# R7FA6T3BB register map
Vendor: Renesas Electronics Corporation; Series: RA6; File version: 1.10.01
CPU: CM33 r0p4, little endian, MPU, FPU, VTOR, 4 interrupt priority bits, 96 interrupts
Registers are 32-bit, read-write, reset 0x0 unless marked. A register's access mark holds for its fields unless they carry their own. Offsets are from the block's base; [hi:lo] are bit positions; {n}, {i} and the like mark numbered series; 'fields as' and 'values as' point back to an identical list.

## I3C — I3C Bus Interface
Base 0x4011F000
0x00 PRTS reset 0x1 — Protocol Selection Register
  [0] PRTMD — Protocol Mode
    0=I3C protocol mode; 1=I2C protocol mode
0x10 CECTL — Clock Enable Control Resisters
  [0] CLKE — Clock Enable
    0=Clock disable; 1=Clock enable
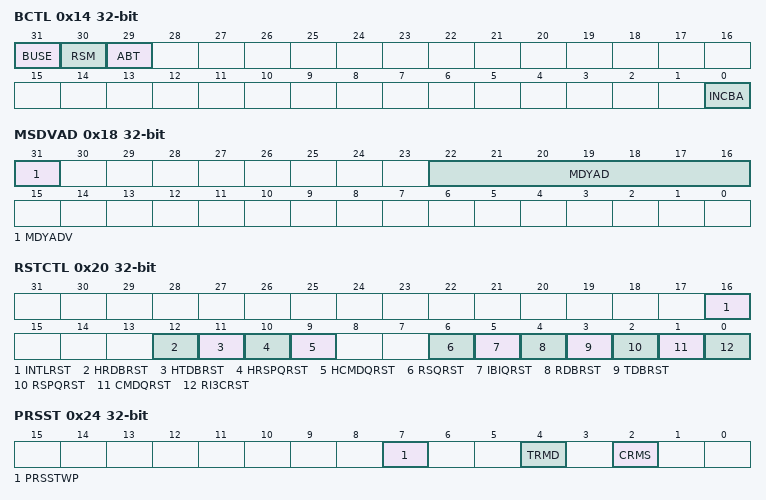
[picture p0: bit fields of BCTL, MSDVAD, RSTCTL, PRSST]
0x14 BCTL — Bus Control Register
  [31] BUSE — Bus Enable
    0=I3C bus operation is disabled; 1=I3C bus operation is enabled
  [30] RSM — Resume
    0=I3C is running; 1=I3C is suspended
  [29] ABT — Abort
    0=I3C is running; 1=I3C has aborted a transfer
  [0] INCBA — Include I3C Broadcast Address
    0=Do not include I3C broadcast address for private transfers; 1=Include I3C broadcast address for private transfers
0x18 MSDVAD — Master Device Address Register
  [31] MDYADV — Master Dynamic Address Valid
    0=The master dynamic address field is not valid; 1=The master dynamic address field is valid
  [22:16] MDYAD — Master Dynamic Address
0x20 RSTCTL — Reset Control Register
  [16] INTLRST — Internal Software Reset
    0=Releases of some registers and internal state; 1=Resets of some registers and internal state
  [12] HRDBRST — High Priority Receive Data Buffer Software Reset
    0=The High Priority Receive Queues in I3C is not flushed; 1=The High Priority Receive Queues in I3C is flushed
  [11] HTDBRST — High Priority Transmit Data Buffer Software Reset
    0=The High Priority Transmit Queues in I3C is not flushed; 1=The High Priority Transmit Queues in I3C is flushed
  [10] HRSPQRST — High Priority Response Queue Software Reset
    0=The High Priority Response Queues in I3C is not flushed; 1=The High Priority Response Queues in I3C is flushed
  [9] HCMDQRST — High Priority Command Queue Software Reset
    0=The High Priority Command Queues in I3C is not flushed; 1=The High Priority Command Queues in I3C is flushed
  [6] RSQRST — Receive Status Queue Software Reset
    0=The Receive Status Queue in I3C is not flushed; 1=The Receive Status Queue in I3C is flushed
  [5] IBIQRST — IBI Queue Software Reset
    0=The IBI Queues in I3C is not flushed; 1=The IBI Queues in I3C is flushed
  [4] RDBRST — Receive Data Buffer Software Reset
    0=The Receive Queues in I3C is not flushed; 1=The Receive Queues in I3C is flushed
  [3] TDBRST — Transmit Data Buffer Software Reset
    0=The Transmit Queues in I3C is not flushed; 1=The Transmit Queues in I3C is flushed
  [2] RSPQRST — Response Queue Software Reset
    0=The Response Queues in I3C is not flushed; 1=The Response Queues in I3C is flushed
  [1] CMDQRST — Command Queue Software Reset
    0=The Command Queues in I3C is not flushed; 1=The Command Queues in I3C is flushed
  [0] RI3CRST — I3C Software Reset
    0=Release I3C reset; 1=Initiate I3C reset
0x24 PRSST — Present State Register
  [7] PRSSTWP wo — Present State Write Protect
    0=CRMS bit is protected; 1=CRMS bit can be written when writing simultaneously with the value of the target bit
  [4] TRMD ro — Transmit/Receive Mode
    0=Receive mode; 1=Transmit mode
  [2] CRMS — Current Master
    0=The Master is not the Current Master, and must request and acquire bus ownership before initiating any transfer; 1=The Master is the Current Master, and as a result can initiate transfers
0x30 INST — Internal Status Register
  [10] INEF — Internal Error Flag
    0=I3C Internal Error has not detected; 1=I3C Internal Error has detected
0x34 INSTE — Internal Status Enable Register
  [10] INEE — Internal Error Enable
    0=Disable INST.INEF; 1=Enable INST.INEF
0x38 INIE — Internal Interrupt Enable Register
  [10] INEIE — Internal Error Interrupt Enable
    0=Disables Non-recoverable Internal Error Interrupt Signal; 1=Enables Non-recoverable Internal Error Interrupt Signal
0x3C INSTFC wo — Internal Status Force Register
  [10] INEFC — Internal Error Force
    0=Not force a specific interrupt; 1=Force a specific interrupt
0x44 DVCT ro — Device Characteristic Table Register
  [23:19] IDX — DCT Table Index
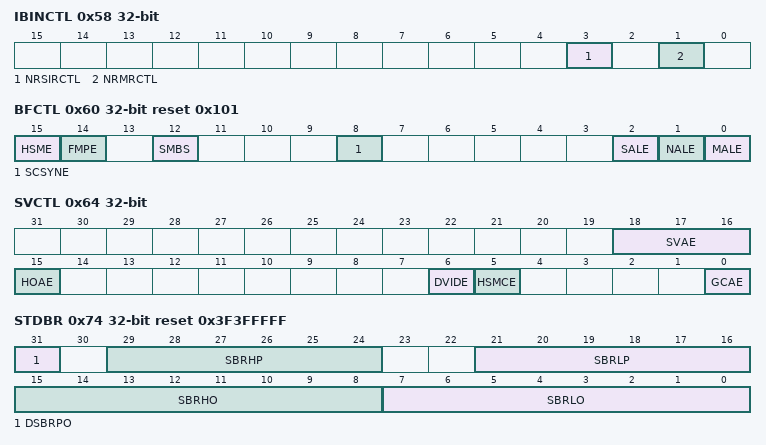
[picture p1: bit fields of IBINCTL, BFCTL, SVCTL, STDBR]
0x58 IBINCTL — IBI Notify Control Register
  [3] NRSIRCTL — Notify Rejected Slave Interrupt Request Control
    0=Do not pass rejected IBI Status to the IBI Queue/Rings, if the incoming SIR is NACKed and is auto-disabled based on DVSIRRJ field in relevant DAT entry; 1=Pass rejected IBI Status to the IBI Queue/Rings, if the incoming SIR is NACKed and is auto-disabled based on DVSIRRJ field in relevant DAT entry
  [1] NRMRCTL — Notify Rejected Master Request Control
    0=Do not pass rejected IBI Status to IBI Queue/Ring, if the incoming Master Request is NACKed and is auto-disabled based on DVMRRJ field in relevant DAT entry; 1=Pass rejected IBI Status to the IBI Queue, if the incoming Master Request is NACKed and is autodisabled based on DVMRRJ field in relevant DAT entry
0x60 BFCTL reset 0x101 — Bus Function Control Register
  [15] HSME — High Speed Mode Enable
    0=Disable High Speed Mode; 1=Enable High Speed Mode
  [14] FMPE — Fast-mode Plus Enable
    0=No Fm+ slope control circuit uses for the I3C_SCL pin and I3C_SDA pin. (n = 0); 1=An Fm+ slope control circuit uses for the I3C_SCL pin and I3C_SDA pin. (n = 0)
  [12] SMBS — SMBus/I2C Bus Selection
    0=The I2C bus select; 1=The SMBus select
  [8] SCSYNE — SCL Synchronous Circuit Enable
    0=No SCL synchronous circuit uses; 1=An SCL synchronous circuit uses
  [2] SALE — Slave Arbitration-Lost Detection Enable
    0=Slave arbitration-lost detection disables; 1=Slave arbitration-lost detection enables
  [1] NALE — NACK Transmission Arbitration-Lost Detection Enable
    0=NACK transmission arbitration-lost detection disables; 1=NACK transmission arbitration-lost detection enables
  [0] MALE — Master Arbitration-Lost Detection Enable
    0=Master arbitration-lost detection disables. Disables the arbitration-lost detection function and does not clear the CRMS and TRMD bits in PRSST automatically when arbitration is lost.; 1=Master arbitration-lost detection enables. Enables the arbitration-lost detection function and clears the CRMS and TRMD bits in PRSST automatically when arbitration is lost.
0x64 SVCTL — Slave Control Register
  [18:16] SVAE — Slave Address Enable n ( n = 0 to 2 )
    0=Slave n disables; 1=Slave n enables
  [15] HOAE — Host Address Enable
    0=Host address detection disables; 1=Host address detection enables
  [6] DVIDE — Device-ID Address Enable
    0=Device-ID address detection disables; 1=Device-ID address detection enables
  [5] HSMCE — Hs-mode Master Code Enable
    0=Hs-mode Master Code Detection disables; 1=Hs-mode Master Code Detection enables
  [0] GCAE — General Call Address Enable
    0=General call address detection disables; 1=General call address detection enables
0x70 REFCKCTL — Reference Clock Control Register
  [2:0] IREFCKS — Internal Reference Clock Selection
    0=TCLK/1 clock; 1=TCLK/2 clock; 2=TCLK/4 clock; 3=TCLK/8 clock; 4=TCLK/16 clock; 5=TCLK/32 clock; 6=TCLK/64 clock; 7=TCLK/128 clock
0x74 STDBR reset 0x3F3FFFFF — Standard Bit Rate Register
  [31] DSBRPO — Double the Standard Bit Rate Period for Open-Drain
    0=The time period set for SBRHO[7:0] and SBRLO[7:0] is not doubled; 1=The time period set for SBRHO[7:0] and SBRLO[7:0] is doubled
  [29:24] SBRHP — Standard Bit Rate High-level Period Push-Pull
  [21:16] SBRLP — Standard Bit Rate Low-level Period Push-Pull
  [15:8] SBRHO — Standard Bit Rate High-level Period Open-Drain
  [7:0] SBRLO — Standard Bit Rate Low-level Period Open-Drain
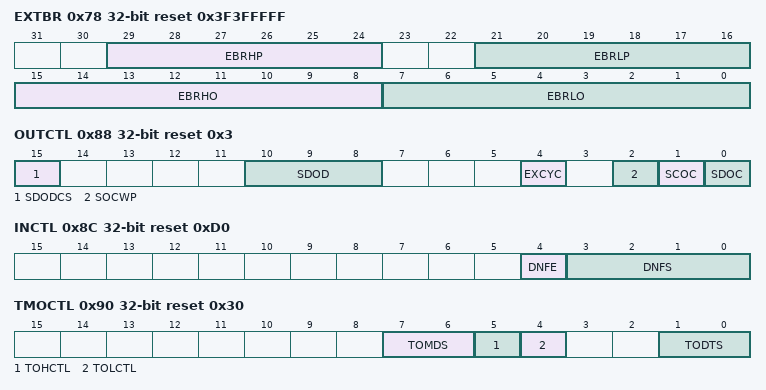
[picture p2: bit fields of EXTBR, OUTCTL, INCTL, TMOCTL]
0x78 EXTBR reset 0x3F3FFFFF — Extended Bit Rate Register
  [29:24] EBRHP — Extended Bit Rate High-level Period Push-Pull
  [21:16] EBRLP — Extended Bit Rate Low-level Period Push-Pull
  [15:8] EBRHO — Extended Bit Rate High-level Period Open-Drain
  [7:0] EBRLO — Extended Bit Rate Low-level Period Open-Drain
0x7C BFRECDT — Bus Free Condition Detection Time Register
  [8:0] FRECYC — Bus Free Condition Detection Cycle
0x80 BAVLCDT — Bus Available Condition Detection Time Register
  [8:0] AVLCYC — Bus Available Condition Detection Cycle
0x84 BIDLCDT — Bus Idle Condition Detection Time Register
  [17:0] IDLCYC — Bus Idle Condition Detection Cycle
0x88 OUTCTL reset 0x3 — Output Control Register
  [15] SDODCS — SDA Output Delay Clock Source Selection
    0=The internal reference clock (I3Cφ) is selected as the clock source of the SDA output delay counter; 1=The internal reference clock divided by 2 (I3Cφ/2) is selected as the clock source of the SDA output delay counter
  [10:8] SDOD — SDA Output Delay
    0=No output delay; 1=1 I3Cφ cycle (When OUTCTL.SDODCS = 0 (I3Cφ)) 1 or 2 I3Cφ cycles (When OUTCTL.SDODCS = 1 (I3Cφ/2)); 2=2 I3Cφ cycles (When OUTCTL.SDODCS = 0 (I3Cφ)) 3 or 4 I3Cφ cycles (When OUTCTL.SDODCS = 1 (I3Cφ/2)); 3=3 I3Cφ cycles (When OUTCTL.SDODCS = 0 (I3Cφ)) 5 or 6 I3Cφ cycles (When OUTCTL.SDODCS = 1 (I3Cφ/2)); 4=4 I3Cφ cycles (When OUTCTL.SDODCS = 0 (I3Cφ)) 7 or 8 I3Cφ cycles (When OUTCTL.SDODCS = 1 (I3Cφ/2)); 5=5 I3Cφ cycles (When OUTCTL.SDODCS = 0 (I3Cφ)) 9 or 10 I3Cφ cycles (When OUTCTL.SDODCS = 1 (I3Cφ/2)); 6=6 I3Cφ cycles (When OUTCTL.SDODCS = 0 (I3Cφ)) 11 or 12 I3Cφ cycles (When OUTCTL.SDODCS = 1 (I3Cφ/2)); 7=7 I3Cφ cycles (When OUTCTL.SDODCS = 0 (I3Cφ)) 13 or 14 I3Cφ cycles (When OUTCTL.SDODCS = 1 (I3Cφ/2))
  [4] EXCYC — Extra SCL Clock Cycle Output
    0=Does not output an extra SCL clock cycle (default); 1=Outputs an extra SCL clock cycle
  [2] SOCWP wo — SCL/SDA Output Control Write Protect
    0=Bits SCOC and SDOC are protected; 1=Bits SCOC and SDOC can be written (When writing simultaneously with the value of the target bit). This bit is read as 0.
  [1] SCOC — SCL Output Control
    0=I3C drives the I3C_SCL pin low; 1=I3C releases the I3C_SCL pin
  [0] SDOC — SDA Output Control
    0=I3C drives the I3C_SDA pin low; 1=I3C releases the I3C_SDA pin
0x8C INCTL reset 0xD0 — Input Control Register
  [4] DNFE — Digital Noise Filter Circuit Enable
    0=No digital noise filter circuit is used; 1=A digital noise filter circuit is used
  [3:0] DNFS — Digital Noise Filter Stage Selection
0x90 TMOCTL reset 0x30 — Timeout Control Register
  [7:6] TOMDS — Timeout Operation Mode Selection
    0=Timeout is detected during the following conditions: The bus is busy (BCST.BFREF = 0) in master mode.I3C’s own slave address is detected and the bus is busy in slave mode.The bus is free (BCST.BFREF = 1) while generation of a START condition is requested (CNDCTL.STCND = 1); 1=Timeout is detected while the bus is busy; 2=Timeout is detected while the bus is free; 3=Setting prohibited
  [5] TOHCTL — Timeout H Count Control
    0=Count is disabled while the I3C_SCL line is at a high level; 1=Count is enabled while the I3C_SCL line is at a high level
  [4] TOLCTL — Timeout L Count Control
    0=Count is disabled while the I3C_SCL line is at a low level; 1=Count is enabled while the I3C_SCL line is at a low level
  [1:0] TODTS — Timeout Detection Time Selection
    0=16bit-timeout; 1=14bit-timeout; 2=8bit-timeout; 3=6bit-timeout
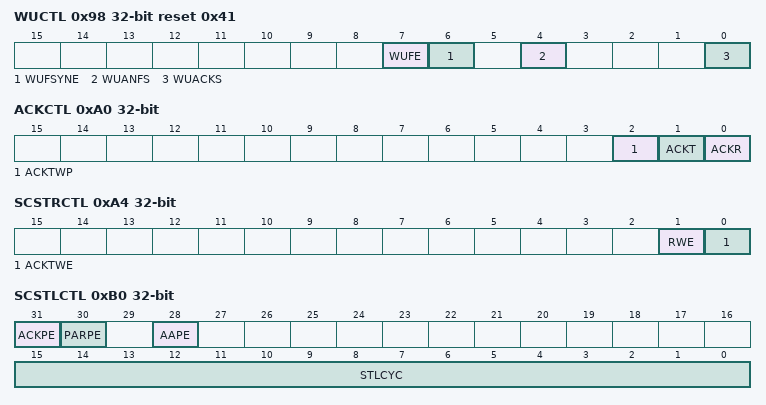
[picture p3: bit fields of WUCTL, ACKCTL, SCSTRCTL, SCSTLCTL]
0x98 WUCTL reset 0x41 — Wake Up Unit Control Register
  [7] WUFE — Wake-Up function Enable
    0=Wake-up function disables; 1=Wake-up function enables
  [6] WUFSYNE — Wake-Up function PCLK Synchronous Enable
    0=I3C asynchronous circuit enable; 1=I3C synchronous circuit enable
  [4] WUANFS — Wake-Up Analog Noise Filter Selection
    0=Do not add the Wake Up analog filter; 1=Add the Wake Up analog filter
  [0] WUACKS — Wake-Up Acknowledge Selection
0xA0 ACKCTL — Acknowledge Control Register
  [2] ACKTWP wo — ACKT Write Protect
    0=The ACKT bit are protected; 1=The ACKT bit can be written (when writing simultaneously with the value of the target bit). This bit is read as 0.
  [1] ACKT — Acknowledge Transmission
    0=A 0 is sent as the acknowledge bit (ACK transmission); 1=A 1 is sent as the acknowledge bit (NACK transmission)
  [0] ACKR ro — Acknowledge Reception
    0=A 0 is received as the acknowledge bit (ACK reception); 1=A 1 is received as the acknowledge bit (NACK reception)
0xA4 SCSTRCTL — SCL Stretch Control Register
  [1] RWE — Receive Wait Enable
    0=No WAIT (The period between ninth clock cycle and first clock cycle is not held low.); 1=WAIT (The period between ninth clock cycle and first clock cycle is held low.) Low-hold is released by reading NTDTBP0
  [0] ACKTWE — Acknowledge Transmission Wait Enable
    0=NTST.RDBFF0 is set at the rising edge of the ninth SCL clock cycle. (The I3C_SCL line is not held low at the falling edge of the eighth clock cycle.); 1=NTST.RDBFF0 is set at the rising edge of the eighth SCL clock cycle. (The I3C_SCL line is held low at the falling edge of the eighth clock cycle.) Low-hold is released by writing a value to the ACKCTL.ACKT bit.
0xB0 SCSTLCTL — SCL Stalling Control Register
  [31] ACKPE — ACK phase Enable
    0=Does not stall the SCL clock during the ACK/NACK phase; 1=Stall the SCL clock during the ACK/NACK phase
  [30] PARPE — Parity Phase Enable
    0=Does not stall the SCL clock during the parity bit period; 1=Stall the SCL clock during the parity bit period
  [28] AAPE — Assigned Address Phase Enable
    0=Does not stall the SCL clock during the address assignment phase; 1=Stall the SCL clock during address assignment phase
  [15:0] STLCYC — Stalling Cycle
0xC0 SVTDLG0 — Slave Transfer Data Length Register 0
  [31:16] STDLG — Slave Transfer Data Length
0x120 STCTL — Synchronous Timing Control Register
  [0] STOE — Synchronous Timing output Enable
    0=Disable; 1=Enable
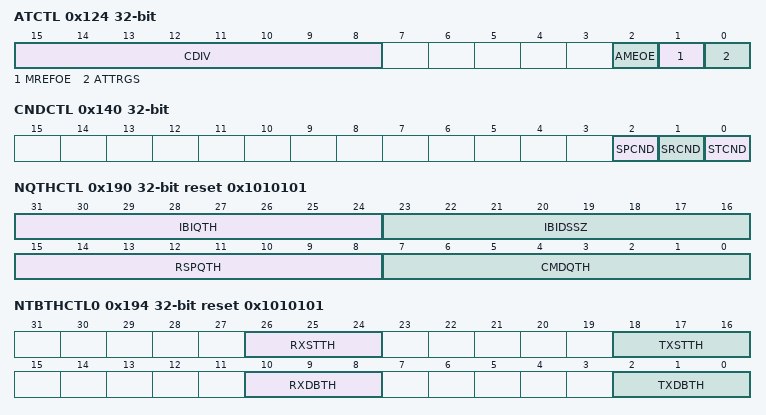
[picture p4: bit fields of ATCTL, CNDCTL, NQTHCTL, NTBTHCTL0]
0x124 ATCTL — Asynchronous Timing Control Register
  [15:8] CDIV — TCLK Counter Divide Setting
  [2] AMEOE — Additional Master-initiated bus Event Output Enable
    0=Disable; 1=Enable
  [1] MREFOE — MREF Output Enable (Capture Event / Counter Overflow)
    0=Disable; 1=Enable
  [0] ATTRGS — Asynchronous Timing Trigger Select
    0=Software trigger; 1=Hardware trigger
0x128 ATTRG — Asynchronous Timing Trigger Register
  [0] ATSTRG wo — Asynchronous Timing Software Trigger
    0=Do nothing; 1=Software trigger (one-shot pulse) output This bit is always read as 0
0x12C ATCCNTE — Asynchronous Timing Contorol Counter enable Register
  [0] ATCE — Asynchronous Timing Counter Enable for MREF, MC2, SC1, SC2.
    0=Disable; 1=Enable
0x140 CNDCTL — Condition Control Register
  [2] SPCND — STOP (P) Condition Issuance
    0=Does not request to issue a STOP condition; 1=Requests to issue a STOP condition
  [1] SRCND — Repeated START (Sr) Condition Issuance
    0=Does not request to issue a Repeated START condition; 1=Requests to issue a Repeated START condition
  [0] STCND — START (S) Condition Issuance
    0=Does not request to issue a START condition; 1=Requests to issue a START condition
0x150 NCMDQP wo — Normal Command Queue Port Register
0x154 NRSPQP ro — Normal Response Queue Port Register
0x158 NTDTBP0 — Normal Transfer Data Buffer Port Register 0
0x158 NTDTBP0_BY 8-bit (alternate view of NTDTBP0) — Normal Transfer Data Buffer Port Register 0
0x17C NIBIQP — Normal IBI Queue Port Register
0x180 NRSQP ro — Normal Receive Status Queue Port Register
0x184 HCMDQP wo — High Priority Command Queue Port Register
0x188 HRSPQP ro — High Priority Response Queue Port Register
0x18C HTDTBP — High Priority Transfer Data Buffer Port Register
0x190 NQTHCTL reset 0x1010101 — Normal Queue Threshold Control Register
  [31:24] IBIQTH — Normal IBI Queue Threshold
    0=I3C Protocol mode (Master): Interrupt is generated when the Outstanding IBI Status count is 1 or more. I3C Protocol mode (Slave): Interrupt is issued when IBI Data Buffer is completely empty.; other=Others (I3C Protocol mode (Master): Interrupt is generated when the Outstanding IBI Status count is N + 1 or more. (N = CMDQTH[7:0]) I3C Protocol mode (Slave): Interrupt is issued when IBI Data Buffer contains N empties.)
  [23:16] IBIDSSZ — Normal IBI Data Segment Size
  [15:8] RSPQTH — Normal Response Queue Threshold
    0=Interrupt is issued when Response Queue contains 1 entry (DWORD); other=Others (Interrupt is triggered when Response Queue contains N+1 entries (DWORD). (N = CMDQTH[7:0]))
  [7:0] CMDQTH — Normal Command Ready Queue Threshold
    0=Interrupt is issued when Command Queue is completely empty; other=Others (Interrupt is issued when Command Queue contains N empties. (N = CMDQTH[7:0]))
0x194 NTBTHCTL0 reset 0x1010101 — Normal Transfer Data Buffer Threshold Control Register 0
  [26:24] RXSTTH — Normal Rx Start Threshold
    0=Wait for 2 empty DWORDs; 1=Wait for 4 empty DWORDs; 2=Wait for 8 empty DWORDs; 3=Wait for 16 empty DWORDs; other=Others (Setting prohibited)
  [18:16] TXSTTH — Normal Tx Start Threshold
    0=Wait for 2 entry DWORDs; 1=Wait for 4 entry DWORDs; 2=Wait for 8 entry DWORDs; 3=Wait for 16 entry DWORDs; other=Others (Setting prohibited)
  [10:8] RXDBTH — Normal Receive Data Buffer Threshold
    0=Interrupt triggers at 2 Rx Buffer entries, DWORDs; 1=Interrupt triggers at 4 Rx Buffer entries, DWORDs; 2=Interrupt triggers at 8 Rx Buffer entries, DWORDs; 3=Interrupt triggers at 16 Rx Buffer entries, DWORDs; other=Others (Setting prohibited)
  [2:0] TXDBTH — Normal Transmit Data Buffer Threshold
    0=Interrupt triggers at 2 Tx Buffer empties, DWORDs; 1=Interrupt triggers at 4 Tx Buffer empties, DWORDs; 2=Interrupt triggers at 8 Tx Buffer empties, DWORDs; 3=Interrupt triggers at 16 Tx Buffer empties, DWORDs; other=Others (Setting prohibited)
0x1C0 NRQTHCTL reset 0x1 — Normal Receive Status Queue Threshold Control Register
  [7:0] RSQTH — Normal Receive Status Queue Threshold
    0=Interrupt is issued when Receive Status Queue contains 1 entry (DWORD); other=Others (Interrupt is triggered when Receive Status Queue contains N+1 entries (DWORD). (N = RSQTH[7:0]))
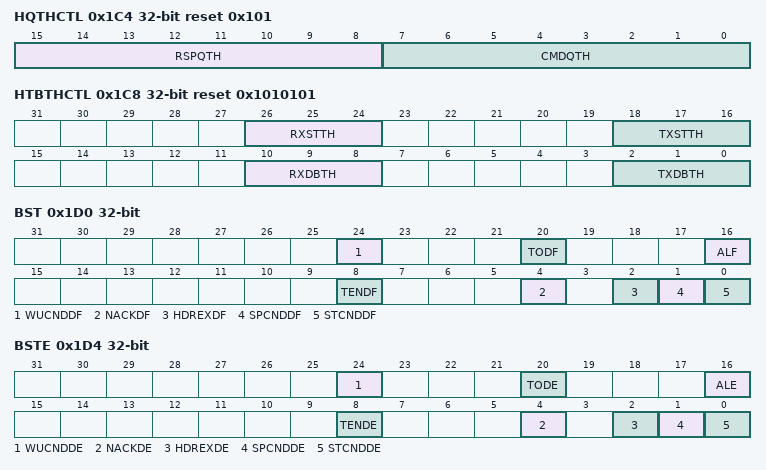
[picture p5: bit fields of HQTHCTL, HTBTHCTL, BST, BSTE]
0x1C4 HQTHCTL reset 0x101 — High Priority Queue Threshold Control Register
  [15:8] RSPQTH — High Priority Response Ready Queue Threshold
    0=Interrupt is issued when High Priority Response Queue contains 1 entry (DWORD); other=Others (Interrupt is triggered when High Priority Response Queue contains N+1 entries (DWORD). (N = RSPQTH[7:0]))
  [7:0] CMDQTH — High Priority Command Ready Queue Threshold
    0=Interrupt is issued when High Priority Command Queue is completely empty; other=Others (Interrupt is issued when High Priority Command Queue contains N entries. (N = CMDQTH[7:0]))
0x1C8 HTBTHCTL reset 0x1010101 — High Priority Transfer Data Buffer Threshold Control Register
  [26:24] RXSTTH — High Priority Rx Start Threshold
    0=Wait for 2 empty DWORDs; other=Others (Setting prohibited)
  [18:16] TXSTTH — High Priority Tx Start Threshold
    0=Wait for 2 entry DWORDs; other=Others (Setting prohibited)
  [10:8] RXDBTH — High Priority Receive Data Buffer Threshold
    0=Interrupt triggers at 2 High Priority Rx Buffer entries, DWORDs; other=Others (Setting prohibited)
  [2:0] TXDBTH — High Priority Transmit Data Buffer Threshold
    0=Interrupt triggers at 2 High Priority Tx Buffer empties, DWORDs; other=Others (Setting prohibited)
0x1D0 BST — Bus Status Register
  [24] WUCNDDF — Wake-Up Condition Detection Flag
    0=Wake-Up is not detected; 1=Wake-Up is detected
  [20] TODF — Timeout Detection Flag
    0=Timeout is not detected; 1=Timeout is detected
  [16] ALF — Arbitration Lost Flag
    0=Arbitration is not lost; 1=Arbitration is lost
  [8] TENDF — Transmit End Flag
    0=Data is being transmitted; 1=Data has been transmitted
  [4] NACKDF — NACK Detection Flag
    0=NACK is not detected; 1=NACK is detected
  [2] HDREXDF — HDR Exit Pattern Detection Flag
    0=HDR Exit Pattern is not detected; 1=HDR Exit Pattern is detected
  [1] SPCNDDF — STOP Condition Detection Flag
    0=STOP condition is not detected; 1=STOP condition is detected
  [0] STCNDDF — START Condition Detection Flag
    0=START condition is not detected; 1=START condition is detected
0x1D4 BSTE — Bus Status Enable Register
  [24] WUCNDDE — Wake-up Condition Detection Enable
    0=Disables Wake-up Condition Detection Status logging; 1=Enables Wake-up Condition Detection Status logging
  [20] TODE — Timeout Detection Enable
    0=Disables Timeout Detection Interrupt Status logging; 1=Enables Timeout Detection Interrupt Status logging
  [16] ALE — Arbitration Lost Enable
    0=Disables Arbitration Lost Interrupt Status logging; 1=Enables Arbitration Lost Interrupt Status logging
  [8] TENDE — Transmit End Enable
    0=Disables Transmit End Interrupt Status logging; 1=Enables Transmit End Interrupt Status logging
  [4] NACKDE — NACK Detection Enable
    0=Disables NACK Detection Interrupt Status logging; 1=Enables NACK Detection Interrupt Status logging
  [2] HDREXDE — HDR Exit Pattern Detection Enable
    0=Disables HDR Exit Pattern Detection Interrupt Status logging; 1=Enables HDR Exit Pattern Detection Interrupt Status logging
  [1] SPCNDDE — STOP Condition Detection Enable
    0=Disables STOP condition Detection Interrupt Status logging; 1=Enables STOP condition Detection Interrupt Status logging
  [0] STCNDDE — START Condition Detection Enable
    0=Disables START condition Detection Interrupt Status logging; 1=Enables START condition Detection Interrupt Status logging
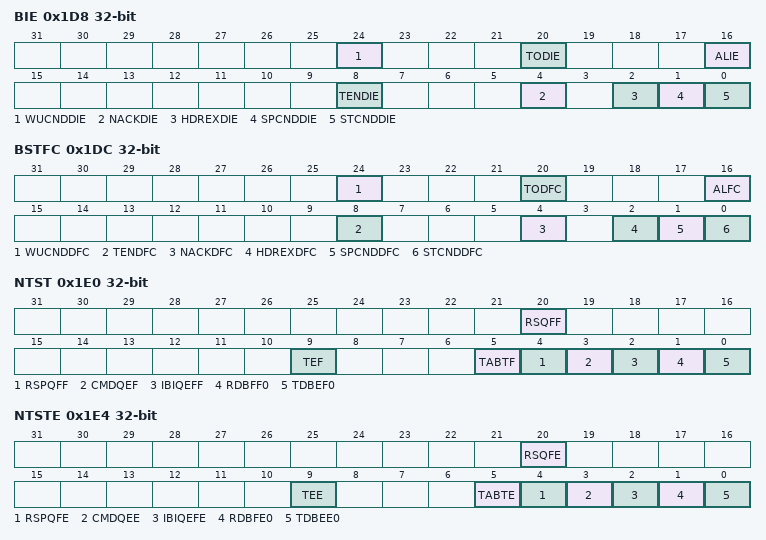
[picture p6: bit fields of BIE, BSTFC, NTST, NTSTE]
0x1D8 BIE — Bus Interrupt Enable Register
  [24] WUCNDDIE — Wake-Up Condition Detection Interrupt Enable
    0=Disables Wake-Up Condition Detection Interrupt Signal; 1=Enables Wake-Up Condition Detection Interrupt Signal
  [20] TODIE — Timeout Detection Interrupt Enable
    0=Disables Timeout Detection Interrupt Signal; 1=Enables Timeout Detection Interrupt Signal
  [16] ALIE — Arbitration Lost Interrupt Enable
    0=Disables Arbitration Lost Interrupt Signal; 1=Enables Arbitration Lost Interrupt Signal
  [8] TENDIE — Transmit End Interrupt Enable
    0=Disables Transmit End Interrupt Signal; 1=Enables Transmit End Interrupt Signal
  [4] NACKDIE — NACK Detection Interrupt Enable
    0=Disables NACK Detection Interrupt Signal; 1=Enables NACK Detection Interrupt Signal
  [2] HDREXDIE — HDR Exit Pattern Detection Interrupt Enable
    0=Disables HDR Exit Pattern Detection Interrupt Signal; 1=Enables HDR Exit Pattern Detection Interrupt Signal
  [1] SPCNDDIE — STOP Condition Detection Interrupt Enable
    0=Disables STOP condition Detection Interrupt Signal; 1=Enables STOP condition Detection Interrupt Signal
  [0] STCNDDIE — START Condition Detection Interrupt Enable
    0=Disables START condition Detection Interrupt Signal; 1=Enables START condition Detection Interrupt Signal
0x1DC BSTFC — Bus Status Force Register
  [24] WUCNDDFC wo — Wake-Up Condition Detection Force
    0=Not Force Wake-Up Condition Detection Interrupt for software testing; 1=Force Wake-Up Condition Detection Interrupt for software testing
  [20] TODFC wo — Timeout Detection Force
    0=Not Force Timeout Detection Interrupt for software testing; 1=Force Timeout Detection Interrupt for software testing
  [16] ALFC wo — Arbitration Lost Force
    0=Not Force Arbitration Lost Interrupt for software testing; 1=Force Arbitration Lost Interrupt for software testing
  [8] TENDFC wo — Transmit End Force
    0=Not Force Transmit End Interrupt for software testing; 1=Force Transmit End Interrupt for software testing
  [4] NACKDFC wo — NACK Detection Force
    0=Not Force NACK Detection Interrupt for software testing; 1=Force NACK Detection Interrupt for software testing
  [2] HDREXDFC wo — HDR Exit Pattern Detection Force
    0=Not Force HDR Exit Pattern Detection Interrupt for software testing; 1=Force HDR Exit Pattern Detection Interrupt for software testing
  [1] SPCNDDFC wo — STOP condition Detection Force
    0=Not Force STOP condition Detection Interrupt for software testing; 1=Force STOP condition Detection Interrupt for software testing
  [0] STCNDDFC wo — START condition Detection Force
    0=Not Force START condition Detection Interrupt for software testing; 1=Force START condition Detection Interrupt for software testing
0x1E0 NTST — Normal Transfer Status Register
  [20] RSQFF — Normal Receive Status Queue Full Flag
    0=The number of Receive Status Queue entries is the NRQTHCTL.RSQTH threshold or less; 1=The number of Receive Status Queue entries is more than the NRQTHCTL.RSQTH threshold
  [9] TEF — Normal Transfer Error Flag
    0=Transfer Error does not occur; 1=Transfer Error occurs. To clear, write 0 to this bit after 1 state is read.
  [5] TABTF — Normal Transfer Abort Flag
    0=Transfer Abort does not occur; 1=Transfer Abort occur. To clear, write 0 to this bit after 1 state is read.
  [4] RSPQFF — Normal Response Queue Full Flag
    0=The number of Response Queue entries is the NQTHCTL.RSPQTH threshold or less; 1=The number of Response Queue entries is more than the NQTHCTL.RSPQTH threshold
  [3] CMDQEF — Normal Command Queue Empty Flag
    0=If the NQTHCTL.CMDQTH = 0: The number of Command Queue empties is less than the Command Queue size. If the NQTHCTL.CMDQTH is other than 0: The number of Command Queue empties is less than the NQTHCTL.CMDQTH threshold.; 1=If the NQTHCTL.CMDQTH = 0: The number of Command Queue empties is the Command Queue size. If the NQTHCTL.CMDQTH is other than 0: 1: The number of Command Queue empties is the NQTHCTL.CMDQTH threshold or more.
  [2] IBIQEFF — Normal IBI Queue Empty/Full Flag
    0=For I3C protocol mode (Master): PRTS.PRTMD bit = 0, PRSST.CRMS bit = 1. The number of IBI Status Queue entries is the NQTHCTL.IBIQTH threshold or less. For I3C protocol mode (Slave) : PRTS.PRTMD bit = 0, PRSST.CRMS bit = 0. If the NQTHCTL.IBIQTH = 0: The number of IBI Data Buffer empties is less than the IBI Data Buffer size. If the NQTHCTL.IBIQTH is other than 0: The number of IBI Data Buffer empties is less than the NQTHCTL.IBIQTH threshold.; 1=For I3C protocol mode (Master): PRTS.PRTMD bit = 0, PRSST.CRMS bit = 1. The number of IBI Status Queue entries is more than the NQTHCTL.IBIQTH threshold. For I3C protocol mode (Slave) : PRTS.PRTMD bit = 0, PRSST.CRMS bit = 0. If the NQTHCTL.IBIQTH = 0: The number of IBI Data Buffer empties is the IBI Data Buffer size. If the NQTHCTL.IBIQTH is other than 0: The number of IBI Data Buffer empties is the NQTHCTL.IBIQTH threshold or more.
  [1] RDBFF0 — Normal Receive Data Buffer Full Flag 0
    0=For I2C protocol mode: PRTS.PRTMD bit = 1. Normal Receive Data Buffer0 contains no receive data. For I3C Protocol mode: PRTS.PRTMD bit = 0. The number of entries in the Normal Receive Data Buffer 0 is less than the NTBTHCTL0.RXDBTH[2:0] threshold.; 1=For I2C protocol mode: PRTS.PRTMD bit = 1. Normal Receive Data Buffer0 contains receive data. For I3C Protocol mode: PRTS.PRTMD bit = 0. The number of entries in the Normal Receive Data Buffer 0 is the NTBTHCTL0.RXDBTH[2:0] threshold or more.
  [0] TDBEF0 — Normal Transmit Data Buffer Empty Flag 0
    0=For I2C protocol mode: PRTS.PRTMD bit = 1. Normal Transmit Data Buffer 0 contains transmit data. For I3C protocol mode: PRTS.PRTMD bit = 0. The number of empties in the Normal Transmit Data Buffer 0 is less than the NTBTHCTL0.TXDBTH[2:0] threshold.; 1=For I2C protocol mode: PRTS.PRTMD bit = 1. Normal Transmit Data Buffer 0 contains no transmit data. For I3C protocol mode: PRTS.PRTMD bit = 0. The number of empties in the Normal Transmit Data Buffer 0 is the NTBTHCTL0.TXDBTH[2:0] threshold or more.
0x1E4 NTSTE — Normal Transfer Status Enable Register
  [20] RSQFE — Normal Receive Status Queue Full Enable
    0=Disables Receive Status Buffer Full Interrupt Status logging; 1=Enables Receive Status Buffer Full Interrupt Status logging
  [9] TEE — Normal Transfer Error Enable
    0=Disables Transfer Error Interrupt Status logging; 1=Enables Transfer Error Interrupt Status logging
  [5] TABTE — Normal Transfer Abort Enable
    0=Disables Transfer Abort Interrupt Status logging; 1=Enables Transfer Abort Interrupt Status logging
  [4] RSPQFE — Normal Response Queue Full Enable
    0=Disables Response Buffer Full Interrupt Status logging; 1=Enables Response Buffer Full Interrupt Status logging
  [3] CMDQEE — Normal Command Queue Empty Enable
    0=Disables Command Buffer Empty Interrupt Status logging; 1=Enables Command Buffer Empty Interrupt Status logging
  [2] IBIQEFE — Normal IBI Queue Empty/Full Enable
    0=Disables IBI Status Buffer Empty/Full Interrupt Status logging; 1=Enables IBI Status Buffer Empty/Full Interrupt Status logging
  [1] RDBFE0 — Normal Receive Data Buffer Full Enable 0
    0=Disables Rx0 Data Buffer Full Interrupt Status logging; 1=Enables Rx0 Data Buffer Full Interrupt Status logging
  [0] TDBEE0 — Normal Transmit Data Buffer Empty Enable 0
    0=Disables Tx0 Data Buffer Empty Interrupt Status logging; 1=Enables Tx0 Data Buffer Empty Interrupt Status logging
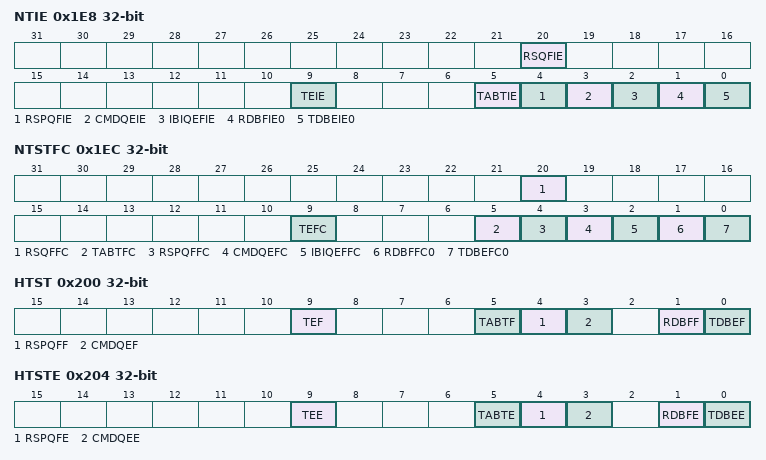
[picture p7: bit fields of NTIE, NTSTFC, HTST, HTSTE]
0x1E8 NTIE — Normal Transfer Interrupt Enable Register
  [20] RSQFIE — Normal Receive Status Queue Full Interrupt Enable
    0=Disables Receive Status Buffer Full Interrupt Signal; 1=Enables Receive Status Buffer Full Interrupt Signal
  [9] TEIE — Normal Transfer Error Interrupt Enable
    0=Disables Transfer Error Interrupt Signal; 1=Enables Transfer Error Interrupt Signal
  [5] TABTIE — Normal Transfer Abort Interrupt Enable
    0=Disables Transfer Abort Interrupt Signal; 1=Enables Transfer Abort Interrupt Signal
  [4] RSPQFIE — Normal Response Queue Full Interrupt Enable
    0=Disables Response Buffer Full Interrupt Signal; 1=Enables Response Buffer Full Interrupt Signal
  [3] CMDQEIE — Normal Command Queue Empty Interrupt Enable
    0=Disables Command Buffer Empty Interrupt Signal; 1=Enables Command Buffer Empty Interrupt Signal
  [2] IBIQEFIE — Normal IBI Queue Empty/Full Interrupt Enable
    0=Disables IBI Status Buffer Empty/Full Interrupt Signal; 1=Enables IBI Status Buffer Empty/Full Interrupt Signal
  [1] RDBFIE0 — Normal Receive Data Buffer Full Interrupt Enable 0
    0=Disables Rx0 Data Buffer Full Interrupt Signal; 1=Enables Rx0 Data Buffer Full Interrupt Signal
  [0] TDBEIE0 — Normal Transmit Data Buffer Empty Interrupt Enable 0
    0=Disables Tx0 Data Buffer Empty Interrupt Signal; 1=Enables Tx0 Data Buffer Empty Interrupt Signal
0x1EC NTSTFC — Normal Transfer Status Force Register
  [20] RSQFFC wo — Normal Receive Status Queue Full Force
    0=Not Force Receive Status Buffer Full Interrupt for software testing; 1=Force Receive Status Buffer Full Interrupt for software testing
  [9] TEFC wo — Normal Transfer Error Force
    0=Not Force Transfer Error Interrupt for software testing; 1=Force Transfer Error Interrupt for software testing
  [5] TABTFC wo — Normal Transfer Abort Force
    0=Not Force Transfer Abort Interrupt for software testing; 1=Force Transfer Abort Interrupt for software testing
  [4] RSPQFFC wo — Normal Response Queue Full Force
    0=Not Force Response Buffer Full Interrupt for software testing; 1=Force Response Buffer Full Interrupt for software testing
  [3] CMDQEFC wo — Normal Command Queue Empty Force
    0=Not Force Command Buffer Empty Interrupt for software testing; 1=Force Command Buffer Empty Interrupt for software testing
  [2] IBIQEFFC wo — Normal IBI Queue Empty/Full Force
    0=Not Force IBI Status Buffer Full Interrupt for software testing; 1=Force IBI Status Buffer Full Interrupt for software testing
  [1] RDBFFC0 wo — Normal Receive Data Buffer Full Force 0
    0=Not Force Rx0 Data Buffer Full Interrupt for software testing; 1=Force Rx0 Data Buffer Full Interrupt for software testing
  [0] TDBEFC0 wo — Normal Transmit Data Buffer Empty Force 0
    0=Not Force Tx0 Data Buffer Empty Interrupt for software testing; 1=Force Tx0 Data Buffer Empty Interrupt for software testing
0x200 HTST — High Priority Transfer Status Register
  [9] TEF — High Priority Transfer Error Flag
    0=High Priority Transfer Error does not occur; 1=High Priority Transfer Error occurs. To clear, write 0 to this bit after 1 is read.
  [5] TABTF — High Priority Transfer Abort Flag
    0=High Priority Transfer Abort does not occur; 1=High Priority Transfer Abort occurs. To clear, write 0 to this bit after 1 is read.
  [4] RSPQFF — High Priority Response Queue Full Flag
    0=The number of High Priority Response Queue entries is less than the HQTHCTL .RSPQTH threshold; 1=The number of High Priority Response Queue entries is the HQTHCTL .RSPQTH threshold or more
  [3] CMDQEF — High Priority Command Queue Empty Flag
    0=If HQTHCTL.CMDQTH is 0, the number of Command Queue empties is less than the Command Queue size. If HQTHCTL.CMDQTH is other than 0, the number of High Priority Command Queue empties is less than the HQTHCTL.CMDQTH threshold.; 1=If HQTHCTL.CMDQTH is 0, the number of Command Queue empties is the Command Queue size. If HQTHCTL.CMDQTH is other than 0, the number of High Priority Command Queue empties is the HQTHCTL.CMDQTH threshold or more.
  [1] RDBFF — High Priority Receive Data Buffer Full Flag
    0=The number of entries in the High Priority Receive Data Buffer is less than the HTBTHCTL.RXDBTH[2:0] threshold; 1=The number of entries in the High Priority Receive Data Buffer is the HTBTHCTL.RXDBTH[2:0] threshold or more
  [0] TDBEF — High Priority Transmit Data Buffer Empty Flag
    0=The number of empties in the High Priority Transmit Data Buffer is less than the HTBTHCTL.TXDBTH[2:0] threshold; 1=The number of empties in the High Priority Transmit Data Buffer is the HTBTHCTL.TXDBTH[2:0] threshold or more
0x204 HTSTE — High Priority Transfer Status Enable Register
  [9] TEE — High Priority Transfer Error Enable
    0=Disables High Priority Transfer Error interrupt Stats logging; 1=Enables High Priority Transfer Error interrupt Stats logging
  [5] TABTE — High Priority Transfer Abort Enable
    0=Disables High PriorityTransfer Abort Interrupt Status logging; 1=Enables High Priority Transfer Abort Interrupt Status logging
  [4] RSPQFE — High Priority Response Queue Full Enable
    0=Disables High Priority Response Buffer Full Interrupt Status logging; 1=Enables High Priority Response Buffer Full Interrupt Status logging
  [3] CMDQEE — High Priority Command Queue Empty Enable
    0=Disables High Priority Command Buffer Empty Interrupt Status logging; 1=Enables High Priority Command Buffer Empty Interrupt Status logging
  [1] RDBFE — High Priority Receive Data Buffer Full Enable
    0=Disables High Priority Receive Data Buffer Full Interrupt Status logging; 1=Enables High Priority Receive Data Buffer Full Interrupt Status logging
  [0] TDBEE — High Priority Transmit Data Buffer Empty Enable
    0=Disables High Priority Transmit Data Buffer Empty Interrupt Status logging; 1=Enables High Priority Transmit Data Buffer Empty Interrupt Status logging
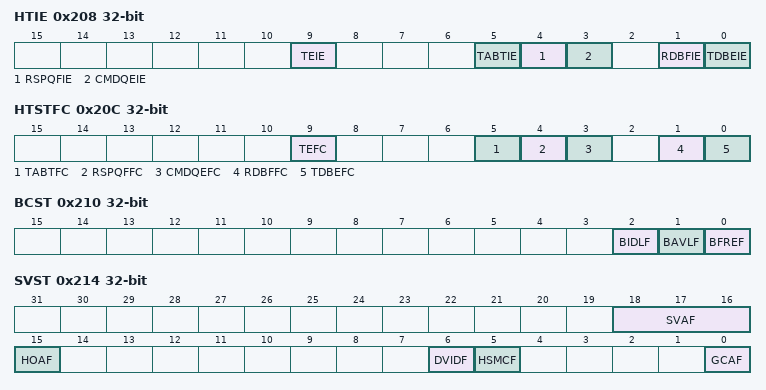
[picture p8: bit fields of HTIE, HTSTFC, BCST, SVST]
0x208 HTIE — High Priority Transfer Interrupt Enable Register
  [9] TEIE — High Priority Transfer Error Interrupt Enable
    0=Disables High Priority Transfer Error Interrupt Signal; 1=Enables High Priority Transfer Error Interrupt Signal
  [5] TABTIE — High Priority Transfer Abort Interrupt Enable
    0=Disables High Priority Transfer Abort interrupt Signal; 1=Enables High Priority Transfer Abort interrupt Signal
  [4] RSPQFIE — High Priority Response Queue Full Interrupt Enable
    0=Disables High Priority Response Buffer Full Interrupt Signal; 1=Enables High Priority Response Buffer Full Interrupt Signal
  [3] CMDQEIE — High Priority Command Queue Empty Interrupt Enable
    0=Disables High Priority Command Buffer Empty Interrupt Signal; 1=Enables High Priority Command Buffer Empty Interrupt Signal
  [1] RDBFIE — High Priority Receive Data Buffer Full Interrupt Enable
    0=Disables High Priority Receive Data Buffer Full Interrupt Signal; 1=Enables High Priority Receive Data Buffer Full Interrupt Signal
  [0] TDBEIE — High Priority Transmit Data Buffer Empty Interrupt Enable
    0=Disables High Priority Transmit Data Buffer Empty Interrupt Signal; 1=Enables High Priority Transmit Data Buffer Empty Interrupt Signal
0x20C HTSTFC — High Priority Transfer Status Force Register
  [9] TEFC wo — High Priority Transfer Error Force
    0=Not Force High Priority Transfer Error Interrupt for software testing; 1=Force High Priority Transfer Error Interrupt for software testing
  [5] TABTFC wo — High Priority Transfer Abort Force
    0=Not Force High Priority Transfer Abort Interrupt for software testing; 1=Force High Priority Transfer Abort Interrupt for software testing
  [4] RSPQFFC wo — High Priority Response Queue Full Force
    0=Not Force High Priority Response Buffer Full Interrupt for software testing; 1=Force High Priority Response Buffer Full Interrupt for software testing
  [3] CMDQEFC wo — High Priority Command Queue Empty Force
    0=Not Force High Priority Command Buffer Empty Interrupt for software testing; 1=Force High Priority Command Buffer Empty Interrupt for software testing
  [1] RDBFFC wo — High Priority Receive Data Buffer Full Force
    0=Not Force High Priority Receive Data Buffer Full Interrupt for software testing; 1=Force High Priority Receive Data Buffer Full Interrupt for software testing
  [0] TDBEFC wo — High Priority Transmit Data Buffer Empty Force
    0=Not Force High Priority Transmit Data Buffer Empty Interrupt for software testing; 1=Force High Priority Transmit Data Buffer Empty Interrupt for software testing
0x210 BCST ro — Bus Condition Status Register
  [2] BIDLF — Bus Idle Detection Flag
    0=Have not Detected Bus Idle; 1=Have Detected Bus Idle
  [1] BAVLF — Bus Available Detection Flag
    0=Have not Detected Bus Available; 1=Have Detected Bus Available
  [0] BFREF — Bus Free Detection Flag
    0=Have not Detected Bus Free; 1=Have Detected Bus Free
0x214 SVST — Slave Status Register
  [18:16] SVAF — Slave Address Detection Flag n ( n = 0 to 2 )
    0=Slave n does not detect; 1=Slave n detect
  [15] HOAF — Host Address Detection Flag
    0=Host address does not detect; 1=Host address detects. This bit set to 1 when the received slave address matches the host address (0001 000).
  [6] DVIDF — Device-ID Address Detection Flag
    0=Device-ID command does not detect; 1=Device-ID command detects. This bit set to 1 when the first frame received immediately after a START condition is detected matches a value of (device ID (1111 100) + 0[W]).
  [5] HSMCF — Hs-mode Master Code Detection Flag
    0=Hs-mode Master Code does not detect; 1=Hs-mode Master Code detects
  [0] GCAF — General Call Address Detection Flag
    0=General call address does not detect; 1=General call address detects
0x218 WUST ro — Wake Up Unit Operating Status Register
  [0] WUASYNF — Wake-up function asynchronous operation status flag
    0=I3C synchronous circuit enable condition; 1=I3C asynchronous circuit enable condition
0x21C MRCCPT ro — MsyncCNT Counter Capture Register
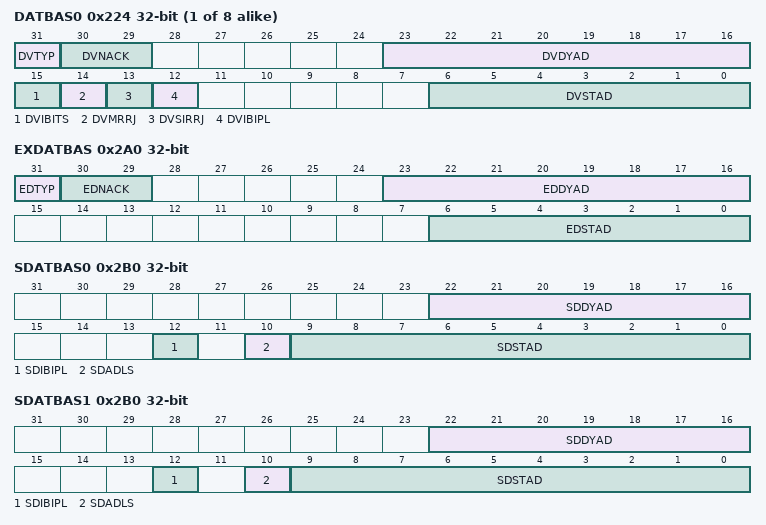
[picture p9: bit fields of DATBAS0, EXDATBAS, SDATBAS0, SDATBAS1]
{0x224+8i} DATBAS{i} (i=0..7) — Device Address Table Basic Register {i}
  [31] DVTYP — Device Type
    0=I3C Device; 1=I2C Device
  [30:29] DVNACK — Device NACK Retry Count
  [23:16] DVDYAD — Device I3C Dynamic Address
  [15] DVIBITS — Device IBI Time-stamp
    0=The Master shall not time-stamp IBIs from this Device with Master Time-stamps; 1=The Master shall time-stamp IBIs for this Device with Master Time-stamps
  [14] DVMRRJ — Device In-Band Master Request Reject
    0=This Device shall ACK Master Requests; 1=This Device shall NACK Master Requests and send the auto-disable command
  [13] DVSIRRJ — Device In-Band Slave Interrupt Request Reject
    0=This Device shall ACK the SIR; 1=This Device shall NACK the SIR and send the auto-disable CCC
  [12] DVIBIPL — Device IBI Payload
    0=IBIs from this Device do not carry a Data Payload; 1=IBIs from this Device do carry a Data Payload
  [6:0] DVSTAD — Device Static Address
0x2A0 EXDATBAS — Extended Device Address Table Basic Register
  [31] EDTYP — Extended Device Type
    0=I3C Device; 1=I2C Device
  [30:29] EDNACK — Extended Device NACK Retry Count
  [23:16] EDDYAD — Extended Device I3C Dynamic Address
  [6:0] EDSTAD — Extended Device Static Address
0x2B0 SDATBAS0 — Slave Device Address Table Basic Register 0
  [22:16] SDDYAD — Slave Device I3C Dynamic Address
  [12] SDIBIPL — Slave Device IBI Payload
    0=IBIs from this device do not carry a data payload; 1=IBIs from this device carry a data payload
  [10] SDADLS — Slave Device Address Length Selection
    0=Slave device address length 7 bits selected; 1=Slave device address length 10 bits selected. (I2C device only)
  [9:0] SDSTAD — Slave Device Static Address
0x2B0 SDATBAS1 (alternate view of SDATBAS0) — Slave Device Address Table Basic Register 1
  fields as SDATBAS0
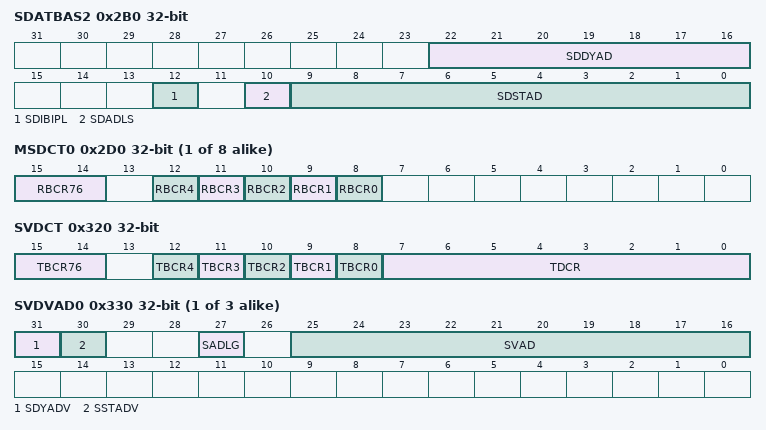
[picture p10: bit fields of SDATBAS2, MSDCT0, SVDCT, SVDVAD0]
0x2B0 SDATBAS2 (alternate view of SDATBAS0) — Slave Device Address Table Basic Register 2
  fields as SDATBAS0
{0x2D0+4i} MSDCT{i} (i=0..7) — Master Device Characteristic Table Register {i}
  [15:14] RBCR76 — Device Role
    0=I3C Slave; 1=I3C Master; other=Others (Setting prohibited)
  [12] RBCR4 — Bridge Identifier
    0=Not a Bridge Device; 1=A Bridge Device
  [11] RBCR3 — Offline Capable
    0=Device will always respond to I3C bus commands; 1=Device will not always respond to I3C bus commands
  [10] RBCR2 — IBI Payload
    0=No data byte follows the accepted IBI; 1=Mandatory one or more data bytes follow the accepted IBI. Data byte continuation is indicated by T-Bit.
  [9] RBCR1 — IBI Request Capable
    0=Not Capable; 1=Capable
  [8] RBCR0 — Max Data Speed Limitation
    0=No Limitation; 1=Limitation
0x320 SVDCT — Slave Device Characteristic Table Register
  [15:14] TBCR76 — Device Role
    0=I3C Slave; 1=I3C Master; other=Others (Setting prohibited)
  [12] TBCR4 — Bridge Identifier
    0=Not a Bridge Device; 1=A Bridge Device
  [11] TBCR3 — Offline Capable
    values as MSDCT0.RBCR3
  [10] TBCR2 — IBI Payload
    values as MSDCT0.RBCR2
  [9] TBCR1 — IBI Request Capable
    0=Not Capable; 1=Capable
  [8] TBCR0 — Max Data Speed Limitation
    0=No Limitation; 1=Limitation
  [7:0] TDCR — Transfar Device Characteristic Register
0x324 SDCTPIDL — Slave Device Characteristic Table Provisional ID Low Register
0x328 SDCTPIDH — Slave Device Characteristic Table Provisional ID High Register
{0x330+4i} SVDVAD{i} (i=0..2) ro — Slave Device Address Register {i}
  [31] SDYADV — Slave Dynamic Address Valid
    0=Dynamic Address is disabled; 1=Dynamic Address is enabled
  [30] SSTADV — Slave Static Address Valid
    0=Slave address is disabled; 1=Slave address is enabled
  [27] SADLG — Slave Address Length
    0=The 7-bit address format is selected; 1=The 10-bit address format is selected
  [25:16] SVAD — Slave Address
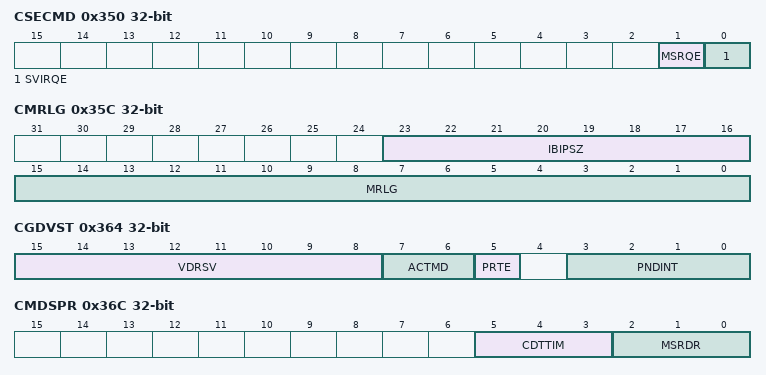
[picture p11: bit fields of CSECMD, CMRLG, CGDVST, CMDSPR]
0x350 CSECMD — CCC Slave Events Command Register
  [1] MSRQE — Mastership Requests Enable
    0=DISABLED: Mastership requests from Secondary Masters is Disabled by the Current Master to control; 1=ENABLED: Mastership requests from Secondary Masters is Enabled by the Current Master to control
  [0] SVIRQE — Slave Interrupt Requests Enable
    0=DISABLED: Slave-initiated Interrupts is Disabled by the Master to control; 1=ENABLED: Slave-initiated Interrupts is Enabled by the Master to control
0x354 CEACTST — CCC Enter Activity State Register
  [3:0] ACTST — Activity State
    1=ENTAS0 (1µs: Latency-free operation); 2=ENTAS1 (100 µs); 4=ENTAS2 (2 ms); 8=ENTAS3 (50 ms: Lowest-activity operation); other=Others (Setting prohibited)
0x358 CMWLG — CCC Max Write Length Register
  [15:0] MWLG — Max Write Length
0x35C CMRLG — CCC Max Read Length Register
  [23:16] IBIPSZ — IBI Payload Size
  [15:0] MRLG — Max Read Length
0x360 CETSTMD ro — CCC Enter Test Mode Register
  [7:0] TSTMD — Test Mode
    0=Exit Test Mode This value removes all I3C devices from Test Mode; 1=Vendor Test Mode This value indicates that I3C devices shall return a random 32bit value in the provisional ID during the Dynamic Address Assignment procedure; other=Others (Setting prohibited)
0x364 CGDVST — CCC Get Device Status Register
  [15:8] VDRSV — Vendor Reserved
  [7:6] ACTMD — Slave Device’s current Activity Mode
    {v}=Activity Mode {v} (v=0..3)
  [5] PRTE — Protocol Error
    0=The Slave has not detected a protocol error since the last Status read; 1=The Slave has detected a protocol error since the last Status read
  [3:0] PNDINT — Pending Interrupt
0x368 CMDSPW — CCC Max Data Speed W (Write) Register
  [2:0] MSWDR — Maximum Sustained Write Data Rate
    0=fscl Max (default value); 1=8 MHz; 2=6 MHz; 3=4 MHz; 4=2 MHz; other=Others (Setting prohibited)
0x36C CMDSPR — CCC Max Data Speed R (Read) Register
  [5:3] CDTTIM — Clock to Data Turnaround Time (TSCO)
    0=8 ns or less (default value); {v}={v+8} ns or less (v=1..4); 7=TSCO is more than 12 ns, and is reported by private agreement; other=Others (Setting prohibited)
  [2:0] MSRDR — Maximum Sustained Read Data Rate
    values as CMDSPW.MSWDR
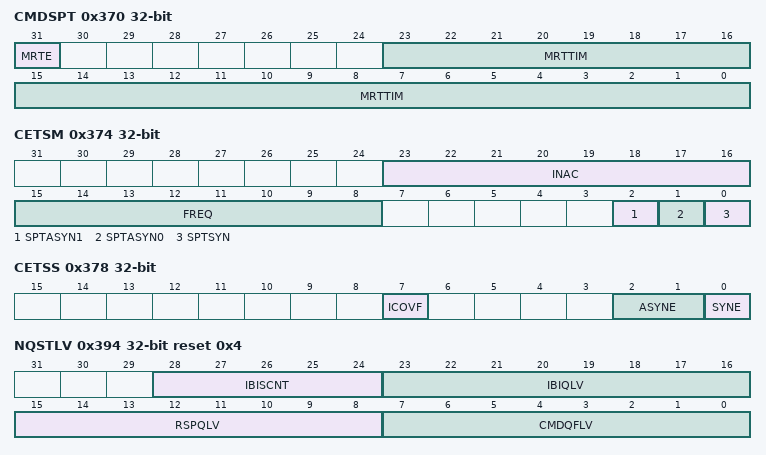
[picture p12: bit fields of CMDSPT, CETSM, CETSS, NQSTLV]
0x370 CMDSPT — CCC Max Data Speed T (Turnaround) Register
  [31] MRTE — Maximum Read Turnaround Time Enable
    0=Disables transmission of the Maximum Read Turnaround Time. (GETMXDS Format 1: Without Turnaround); 1=Enables transmission of the Maximum Read Turnaround Time. (GETMXDS Format 2: With Turnaround)
  [23:0] MRTTIM — Maximum Read Turnaround Time
0x374 CETSM — CCC Exchange Timing Support Information M (Mode) Register
  [23:16] INAC — Inaccuracy Byte
  [15:8] FREQ — Frequency Byte
  [2] SPTASYN1 — Support Async Mode 1
    0=Async Mode 1 is not supported; 1=Async Mode 1 is supported
  [1] SPTASYN0 — Support Async Mode 0
    0=Async Mode 0 is not supported; 1=Async Mode 0 is supported
  [0] SPTSYN — Supports Sync Mode
    0=Sync Mode is not supported; 1=Sync Mode is supported
0x378 CETSS — CCC Exchange Timing Support Information S (State) Register
  [7] ICOVF — Internal Counter Overflow
    0=Slave has not experienced a counter overflow since the most recent previous check; 1=Slave experienced a counter overflow since the most recent previous check
  [2:1] ASYNE — Async Mode Enabled
    0=All Mode Disable; 1=Async Mode 0 Enabled; 2=Async Mode 1 Enabled; other=Others (Setting prohibited)
  [0] SYNE — Sync Mode Enabled
    0=Sync Mode Disabled; 1=Sync Mode Enabled
0x380 BITCNT ro — Bit Count Register
  [4:0] BCNT — Bit Counter
0x394 NQSTLV ro reset 0x4 — Normal Queue Status Level Register
  [28:24] IBISCNT — Normal IBI Status Count
  [23:16] IBIQLV — Normal IBI Queue Level
  [15:8] RSPQLV — Normal Response Queue Level
  [7:0] CMDQFLV — Normal Command Queue Free Level
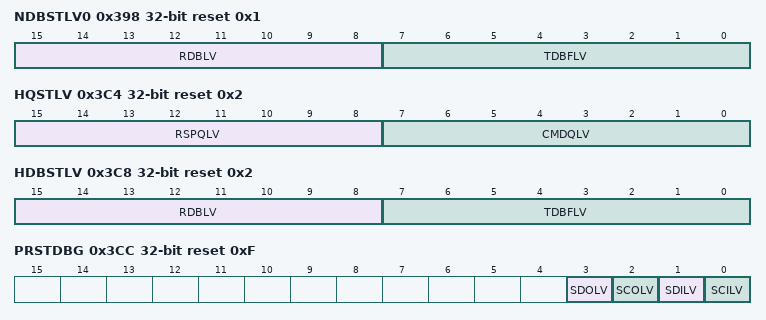
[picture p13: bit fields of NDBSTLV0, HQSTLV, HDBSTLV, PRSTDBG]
0x398 NDBSTLV0 ro reset 0x1 — Normal Data Buffer Status Level Register 0
  [15:8] RDBLV — Normal Receive Data Buffer Level
  [7:0] TDBFLV — Normal Transmit Data Buffer Free Level
0x3C0 NRSQSTLV ro — Normal Receive Status Queue Status Level Register
  [7:0] RSQLV — Normal Receive Status Queue Level
0x3C4 HQSTLV ro reset 0x2 — High Priority Queue Status Level Register
  [15:8] RSPQLV — High Priority Response Queue Level
  [7:0] CMDQLV — High Priority Command Queue Level
0x3C8 HDBSTLV ro reset 0x2 — High Priority Data Buffer Status Level Register
  [15:8] RDBLV — High Priority Receive Data Buffer Level
  [7:0] TDBFLV — High Priority Transmit Data Buffer Free Level
0x3CC PRSTDBG ro reset 0xF — Present State Debug Register
  [3] SDOLV — SDA Output Level
    0=I3C has driven the SDA pin low; 1=I3C has released the SDA pin
  [2] SCOLV — SCL Output Level
    0=I3C has driven the SCL pin low; 1=I3C has released the SCL pin
  [1] SDILV — SDA Line Signal Level
  [0] SCILV — SCL Line Signal Level
0x3D0 MSERRCNT ro — Master Error Counters Register
  [7:0] M2ECNT — M2 Error Counter
0x3E0 SC1CPT ro — SC1 Capture monitor Register
  [15:0] SC1C — SC1 Capture
0x3E4 SC2CPT ro — SC2 Capture monitor Register
  [15:0] SC2C — SC2 Capture
